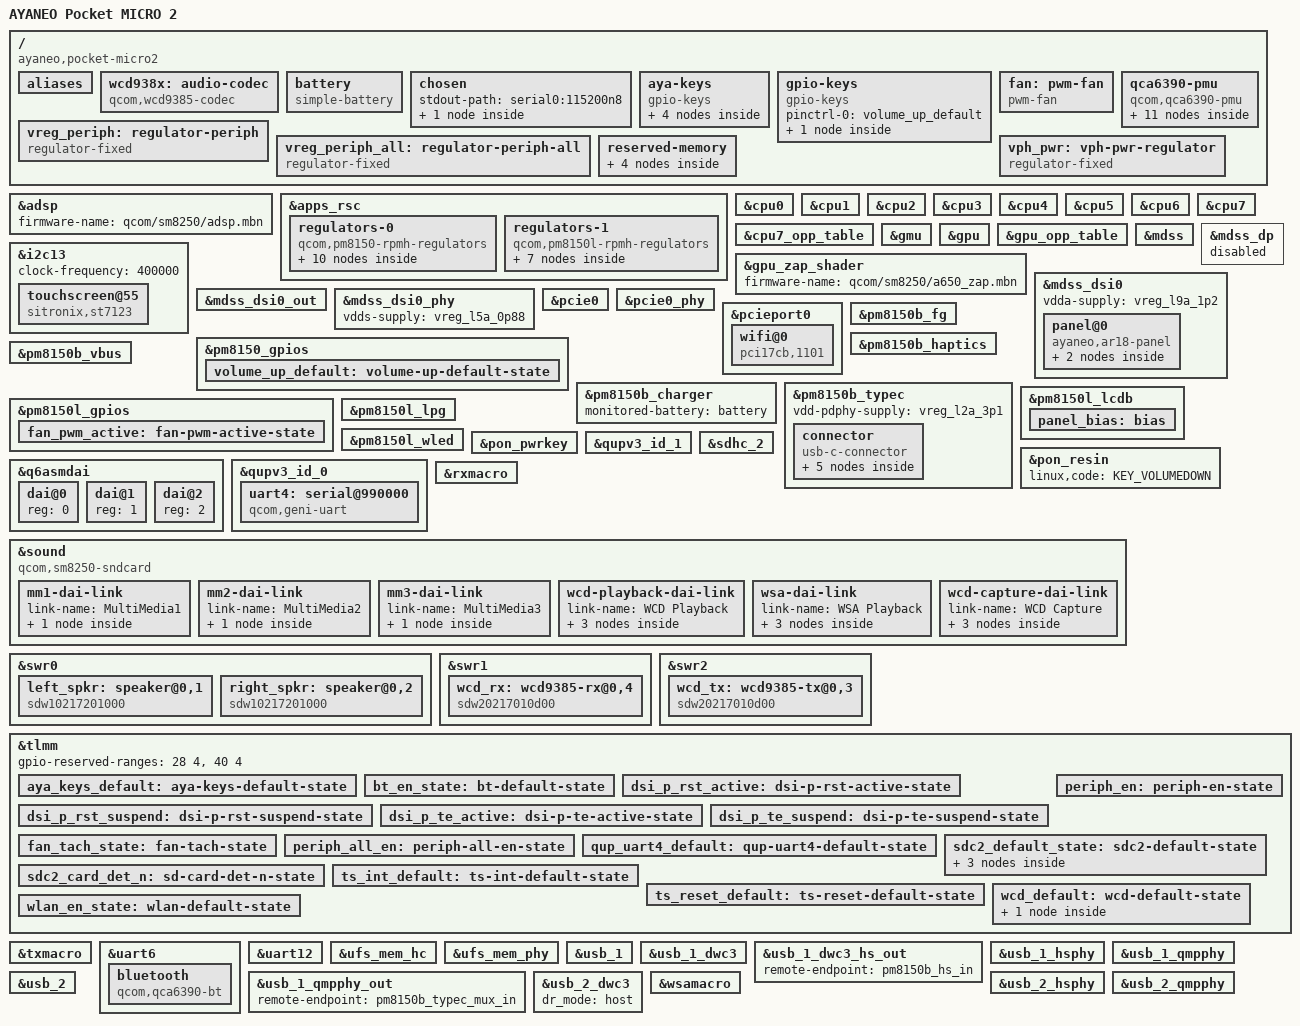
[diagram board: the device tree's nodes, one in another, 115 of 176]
// SPDX-License-Identifier: BSD-3-Clause

/dts-v1/;

#include <dt-bindings/gpio/gpio.h>
#include <dt-bindings/input/input.h>
#include <dt-bindings/interconnect/qcom,icc.h>
#include <dt-bindings/regulator/qcom,rpmh-regulator.h>
#include <dt-bindings/sound/qcom,q6afe.h>
#include <dt-bindings/sound/qcom,q6asm.h>
#include <dt-bindings/usb/pd.h>
#include "sm8250.dtsi"
#include "pm8150.dtsi"
#include "pm8150b.dtsi"
#include "pm8150l.dtsi"

/ {
	model = "AYANEO Pocket MICRO 2";
	compatible = "ayaneo,pocket-micro2", "qcom,sm8250";
	qcom,msm-id = <0x164 0x20001>;
	qcom,board-id = <0x0b 0x00>;

	aliases {
		serial0 = &uart12;
		serial1 = &uart6;
		serial2 = &uart4;
	};

	wcd938x: audio-codec {
		compatible = "qcom,wcd9385-codec";

		pinctrl-names = "default";
		pinctrl-0 = <&wcd_default>;

		reset-gpios = <&tlmm 32 GPIO_ACTIVE_LOW>;

		vdd-buck-supply = <&vreg_s4a_1p8>;
		vdd-rxtx-supply = <&vreg_s4a_1p8>;
		vdd-io-supply = <&vreg_s4a_1p8>;
		vdd-mic-bias-supply = <&vreg_bob>;

		qcom,micbias1-microvolt = <1800000>;
		qcom,micbias2-microvolt = <1800000>;
		qcom,micbias3-microvolt = <1800000>;
		qcom,micbias4-microvolt = <1800000>;
		qcom,mbhc-buttons-vthreshold-microvolt = <75000 150000 237000 500000 500000 500000 500000 500000>;
		qcom,mbhc-headset-vthreshold-microvolt = <1700000>;
		qcom,mbhc-headphone-vthreshold-microvolt = <50000>;
		qcom,hphl-jack-type-normally-closed;
		qcom,ground-jack-type-normally-closed;
		qcom,rx-device = <&wcd_rx>;
		qcom,tx-device = <&wcd_tx>;

		#sound-dai-cells = <1>;
	};

	battery: battery {
		compatible = "simple-battery";

		charge-full-design-microamp-hours = <3950000>;
		voltage-min-design-microvolt = <3600000>;
		voltage-max-design-microvolt = <4450000>;
		constant-charge-current-max-microamp = <3000000>;
	};

	chosen {
		#address-cells = <2>;
		#size-cells = <2>;
		ranges;

		stdout-path = "serial0:115200n8";

		framebuffer: framebuffer@9c000000 {
			compatible = "simple-framebuffer";
			reg = <0x0 0x9c000000 0x0 0x258000>;
			width = <640>;
			height = <960>;
			stride = <(640 * 4)>;
			format = "a8r8g8b8";
		};
	};

	aya-keys {
		compatible = "gpio-keys";
		label = "aya-keys";
		pinctrl-0 = <&aya_keys_default>;
		pinctrl-names = "default";

		key-home {
			label = "Home";
			linux,code = <KEY_PROG1>;
			gpios = <&tlmm 110 GPIO_ACTIVE_LOW>;
			debounce-interval = <15>;
		};

		key-lc {
			label = "LC";
			linux,code = <KEY_PROG3>;
			gpios = <&tlmm 113 GPIO_ACTIVE_LOW>;
			debounce-interval = <15>;
		};

		key-rc {
			label = "RC";
			linux,code = <KEY_PROG4>;
			gpios = <&tlmm 111 GPIO_ACTIVE_LOW>;
			debounce-interval = <15>;
		};

		key-space {
			label = "Space";
			linux,code = <KEY_PROG2>;
			gpios = <&tlmm 109 GPIO_ACTIVE_LOW>;
			debounce-interval = <15>;
		};
	};

	gpio-keys {
		compatible = "gpio-keys";
		pinctrl-0 = <&volume_up_default>;
		pinctrl-names = "default";

		key-vol-up {
			label = "Volume Up";
			linux,code = <KEY_VOLUMEUP>;
			gpios = <&pm8150_gpios 6 GPIO_ACTIVE_LOW>;
			wakeup-source;
		};
	};

	fan: pwm-fan {
		compatible = "pwm-fan";
		cooling-levels = <0 100 130 160 190 210 230 245 255>;
		#cooling-cells = <2>;
		pwms = <&pm8150l_lpg 4 40000>;
		interrupt-parent = <&tlmm>;
		interrupts = <51 IRQ_TYPE_EDGE_FALLING>;
		pulses-per-revolution = <2>;
		pinctrl-names = "default";
		pinctrl-0 = <&fan_pwm_active>, <&fan_tach_state>;
	};

	qca6390-pmu {
		compatible = "qcom,qca6390-pmu";

		pinctrl-names = "default";
		pinctrl-0 = <&bt_en_state>, <&wlan_en_state>;

		vddaon-supply = <&vreg_s6a_0p95>;
		vddrfa1p3-supply = <&vreg_s8c_1p3>;
		vddrfa1p9-supply = <&vreg_s5a_1p9>;
		vddpcie1p3-supply = <&vreg_s8c_1p3>;
		vddpcie1p9-supply = <&vreg_s5a_1p9>;
		vddio-supply = <&vreg_s4a_1p8>;

		wlan-enable-gpios = <&tlmm 20 GPIO_ACTIVE_HIGH>;
		bt-enable-gpios = <&tlmm 21 GPIO_ACTIVE_HIGH>;

		regulators {
			vreg_pmu_rfa_cmn: ldo0 {
				regulator-name = "vreg_pmu_rfa_cmn";
			};

			vreg_pmu_aon_0p59: ldo1 {
				regulator-name = "vreg_pmu_aon_0p59";
			};

			vreg_pmu_wlcx_0p8: ldo2 {
				regulator-name = "vreg_pmu_wlcx_0p8";
			};

			vreg_pmu_wlmx_0p85: ldo3 {
				regulator-name = "vreg_pmu_wlmx_0p85";
			};

			vreg_pmu_btcmx_0p85: ldo4 {
				regulator-name = "vreg_pmu_btcmx_0p85";
			};

			vreg_pmu_rfa_0p8: ldo5 {
				regulator-name = "vreg_pmu_rfa_0p8";
			};

			vreg_pmu_rfa_1p2: ldo6 {
				regulator-name = "vreg_pmu_rfa_1p2";
			};

			vreg_pmu_rfa_1p7: ldo7 {
				regulator-name = "vreg_pmu_rfa_1p7";
			};

			vreg_pmu_pcie_0p9: ldo8 {
				regulator-name = "vreg_pmu_pcie_0p9";
			};

			vreg_pmu_pcie_1p8: ldo9 {
				regulator-name = "vreg_pmu_pcie_1p8";
			};
		};
	};

	vreg_periph: regulator-periph {
		compatible = "regulator-fixed";
		regulator-name = "periph";
		gpio = <&tlmm 119 GPIO_ACTIVE_HIGH>;
		enable-active-high;
		regulator-always-on;
		regulator-boot-on;
		pinctrl-0 = <&periph_en>;
		pinctrl-names = "default";
	};

	vreg_periph_all: regulator-periph-all {
		compatible = "regulator-fixed";
		regulator-name = "periph_all";
		gpio = <&tlmm 12 GPIO_ACTIVE_HIGH>;
		enable-active-high;
		regulator-always-on;
		regulator-boot-on;
		pinctrl-0 = <&periph_all_en>;
		pinctrl-names = "default";
	};

	reserved-memory {
		cont_splash_mem: splash_region@9c000000 {
			reg = <0x0 0x9c000000 0x0 0x2300000>;
			no-map;
		};

		reserved_ea000000_mem: reserved@ea000000 {
			reg = <0x0 0xea000000 0x0 0x15c00000>;
			no-map;
		};

		reserved_ffc00000_mem: reserved@ffc00000 {
			reg = <0x0 0xffc00000 0x0 0x20000>;
			no-map;
		};

		linux,cma {
			compatible = "shared-dma-pool";
			reusable;
			size = <0x0 0x10000000>;
			linux,cma-default;
		};
	};

	vph_pwr: vph-pwr-regulator {
		compatible = "regulator-fixed";
		regulator-name = "vph_pwr";
		regulator-min-microvolt = <3700000>;
		regulator-max-microvolt = <3700000>;
		regulator-always-on;
	};
};

&adsp {
	status = "okay";
	firmware-name = "qcom/sm8250/adsp.mbn";
};

&apps_rsc {
	regulators-0 {
		compatible = "qcom,pm8150-rpmh-regulators";
		qcom,pmic-id = "a";

		vdd-s1-supply = <&vph_pwr>;
		vdd-s2-supply = <&vph_pwr>;
		vdd-s3-supply = <&vph_pwr>;
		vdd-s4-supply = <&vph_pwr>;
		vdd-s5-supply = <&vph_pwr>;
		vdd-s6-supply = <&vph_pwr>;
		vdd-s7-supply = <&vph_pwr>;
		vdd-s8-supply = <&vph_pwr>;
		vdd-s9-supply = <&vph_pwr>;
		vdd-s10-supply = <&vph_pwr>;
		vdd-l2-l10-supply = <&vreg_bob>;
		vdd-l3-l4-l5-l18-supply = <&vreg_s6a_0p95>;
		vdd-l6-l9-supply = <&vreg_s8c_1p3>;
		vdd-l7-l12-l14-l15-supply = <&vreg_s5a_1p9>;
		vdd-l13-l16-l17-supply = <&vreg_bob>;

		vreg_l2a_3p1: ldo2 {
			regulator-name = "vreg_l2a_3p1";
			regulator-min-microvolt = <3072000>;
			regulator-max-microvolt = <3072000>;
			regulator-initial-mode = <RPMH_REGULATOR_MODE_HPM>;
		};

		vreg_l5a_0p88: ldo5 {
			regulator-name = "vreg_l5a_0p88";
			regulator-min-microvolt = <880000>;
			regulator-max-microvolt = <880000>;
			regulator-initial-mode = <RPMH_REGULATOR_MODE_HPM>;
		};

		vreg_l6a_1p2: ldo6 {
			regulator-name = "vreg_l6a_1p2";
			regulator-min-microvolt = <1200000>;
			regulator-max-microvolt = <1200000>;
			regulator-initial-mode = <RPMH_REGULATOR_MODE_HPM>;
		};

		vreg_l9a_1p2: ldo9 {
			regulator-name = "vreg_l9a_1p2";
			regulator-min-microvolt = <1200000>;
			regulator-max-microvolt = <1200000>;
			regulator-initial-mode = <RPMH_REGULATOR_MODE_HPM>;
			regulator-always-on;
			regulator-boot-on;
		};

		vreg_l12a_1p8: ldo12 {
			regulator-name = "vreg_l12a_1p8";
			regulator-min-microvolt = <1800000>;
			regulator-max-microvolt = <1800000>;
			regulator-initial-mode = <RPMH_REGULATOR_MODE_HPM>;
		};

		vreg_l17a_3p0: ldo17 {
			regulator-name = "vreg_l17a_3p0";
			regulator-min-microvolt = <2856000>;
			regulator-max-microvolt = <3008000>;
			regulator-initial-mode = <RPMH_REGULATOR_MODE_HPM>;
		};

		vreg_l18a_0p92: ldo18 {
			regulator-name = "vreg_l18a_0p92";
			regulator-min-microvolt = <800000>;
			regulator-max-microvolt = <912000>;
			regulator-initial-mode = <RPMH_REGULATOR_MODE_HPM>;
			regulator-always-on;
			regulator-boot-on;
		};

		vreg_s4a_1p8: smps4 {
			regulator-name = "vreg_s4a_1p8";
			regulator-min-microvolt = <1800000>;
			regulator-max-microvolt = <1800000>;
			regulator-initial-mode = <RPMH_REGULATOR_MODE_HPM>;
			regulator-always-on;
			regulator-boot-on;
		};

		vreg_s5a_1p9: smps5 {
			regulator-name = "vreg_s5a_1p9";
			regulator-min-microvolt = <1904000>;
			regulator-max-microvolt = <2000000>;
			regulator-initial-mode = <RPMH_REGULATOR_MODE_HPM>;
		};

		vreg_s6a_0p95: smps6 {
			regulator-name = "vreg_s6a_0p95";
			regulator-min-microvolt = <920000>;
			regulator-max-microvolt = <1128000>;
			regulator-initial-mode = <RPMH_REGULATOR_MODE_HPM>;
		};
	};

	regulators-1 {
		compatible = "qcom,pm8150l-rpmh-regulators";
		qcom,pmic-id = "c";

		vdd-s1-supply = <&vph_pwr>;
		vdd-s2-supply = <&vph_pwr>;
		vdd-s3-supply = <&vph_pwr>;
		vdd-s4-supply = <&vph_pwr>;
		vdd-s5-supply = <&vph_pwr>;
		vdd-s6-supply = <&vph_pwr>;
		vdd-s7-supply = <&vph_pwr>;
		vdd-s8-supply = <&vph_pwr>;
		vdd-l1-l8-supply = <&vreg_s4a_1p8>;
		vdd-l2-l3-supply = <&vreg_s8c_1p3>;
		vdd-l4-l5-l6-supply = <&vreg_bob>;
		vdd-l7-l11-supply = <&vreg_bob>;
		vdd-l9-l10-supply = <&vreg_bob>;
		vdd-bob-supply = <&vph_pwr>;

		vreg_bob: bob {
			regulator-name = "vreg_bob";
			regulator-min-microvolt = <3008000>;
			regulator-max-microvolt = <4000000>;
			regulator-initial-mode = <RPMH_REGULATOR_MODE_AUTO>;
		};

		vreg_l1c_ts_1p8: ldo1 {
			regulator-name = "vreg_l1c_ts_1p8";
			regulator-min-microvolt = <1800000>;
			regulator-max-microvolt = <1800000>;
			regulator-initial-mode = <RPMH_REGULATOR_MODE_HPM>;
			regulator-always-on;
		};

		vreg_l6c_2p96: ldo6 {
			regulator-name = "vreg_l6c_2p96";
			regulator-min-microvolt = <1800000>;
			regulator-max-microvolt = <2960000>;
			regulator-initial-mode = <RPMH_REGULATOR_MODE_HPM>;
		};

		vreg_l9c_2p96: ldo9 {
			regulator-name = "vreg_l9c_2p96";
			regulator-min-microvolt = <2704000>;
			regulator-max-microvolt = <2960000>;
			regulator-initial-mode = <RPMH_REGULATOR_MODE_HPM>;
		};

		vreg_l10c_3p0: ldo10 {
			regulator-name = "vreg_l10c_3p0";
			regulator-min-microvolt = <3000000>;
			regulator-max-microvolt = <3312000>;
			regulator-initial-mode = <RPMH_REGULATOR_MODE_HPM>;
			regulator-always-on;
		};

		vreg_l11c_3p3: ldo11 {
			regulator-name = "vreg_l11c_3p3";
			regulator-min-microvolt = <3296000>;
			regulator-max-microvolt = <3296000>;
			regulator-initial-mode = <RPMH_REGULATOR_MODE_HPM>;
			regulator-always-on;
		};

		vreg_s8c_1p3: smps8 {
			regulator-name = "vreg_s8c_1p3";
			regulator-min-microvolt = <1352000>;
			regulator-max-microvolt = <1352000>;
			regulator-initial-mode = <RPMH_REGULATOR_MODE_HPM>;
		};
	};
};

&cpu0 {
	interconnects = <&gem_noc MASTER_AMPSS_M0 QCOM_ICC_TAG_ACTIVE_ONLY &mc_virt SLAVE_EBI_CH0 QCOM_ICC_TAG_ACTIVE_ONLY>,
			<&epss_l3 MASTER_OSM_L3_APPS &epss_l3 SLAVE_OSM_L3>;
};

&cpu1 {
	interconnects = <&gem_noc MASTER_AMPSS_M0 QCOM_ICC_TAG_ACTIVE_ONLY &mc_virt SLAVE_EBI_CH0 QCOM_ICC_TAG_ACTIVE_ONLY>,
			<&epss_l3 MASTER_OSM_L3_APPS &epss_l3 SLAVE_OSM_L3>;
};

&cpu2 {
	interconnects = <&gem_noc MASTER_AMPSS_M0 QCOM_ICC_TAG_ACTIVE_ONLY &mc_virt SLAVE_EBI_CH0 QCOM_ICC_TAG_ACTIVE_ONLY>,
			<&epss_l3 MASTER_OSM_L3_APPS &epss_l3 SLAVE_OSM_L3>;
};

&cpu3 {
	interconnects = <&gem_noc MASTER_AMPSS_M0 QCOM_ICC_TAG_ACTIVE_ONLY &mc_virt SLAVE_EBI_CH0 QCOM_ICC_TAG_ACTIVE_ONLY>,
			<&epss_l3 MASTER_OSM_L3_APPS &epss_l3 SLAVE_OSM_L3>;
};

&cpu4 {
	interconnects = <&gem_noc MASTER_AMPSS_M0 QCOM_ICC_TAG_ACTIVE_ONLY &mc_virt SLAVE_EBI_CH0 QCOM_ICC_TAG_ACTIVE_ONLY>,
			<&epss_l3 MASTER_OSM_L3_APPS &epss_l3 SLAVE_OSM_L3>;
};

&cpu5 {
	interconnects = <&gem_noc MASTER_AMPSS_M0 QCOM_ICC_TAG_ACTIVE_ONLY &mc_virt SLAVE_EBI_CH0 QCOM_ICC_TAG_ACTIVE_ONLY>,
			<&epss_l3 MASTER_OSM_L3_APPS &epss_l3 SLAVE_OSM_L3>;
};

&cpu6 {
	interconnects = <&gem_noc MASTER_AMPSS_M0 QCOM_ICC_TAG_ACTIVE_ONLY &mc_virt SLAVE_EBI_CH0 QCOM_ICC_TAG_ACTIVE_ONLY>,
			<&epss_l3 MASTER_OSM_L3_APPS &epss_l3 SLAVE_OSM_L3>;
};

&cpu7 {
	interconnects = <&gem_noc MASTER_AMPSS_M0 QCOM_ICC_TAG_ACTIVE_ONLY &mc_virt SLAVE_EBI_CH0 QCOM_ICC_TAG_ACTIVE_ONLY>,
			<&epss_l3 MASTER_OSM_L3_APPS &epss_l3 SLAVE_OSM_L3>;
};

&cpu7_opp_table {
	/delete-node/ opp-2745600000;
	/delete-node/ opp-2841600000;
};

&gmu {
	status = "okay";
};

&gpu {
	status = "okay";
};

&gpu_opp_table {
	/delete-node/ opp-925000000;
	/delete-node/ opp-905000000;
	/delete-node/ opp-855000000;
	/delete-node/ opp-800000000;
	/delete-node/ opp-750000000;
	/delete-node/ opp-725000000;
	/delete-node/ opp-700000000;
	/delete-node/ opp-670000000;
	/delete-node/ opp-650000000;
};

&gpu_zap_shader {
	firmware-name = "qcom/sm8250/a650_zap.mbn";
};

&i2c13 {
	status = "okay";
	clock-frequency = <400000>;

	touchscreen@55 {
		compatible = "sitronix,st7123";
		reg = <0x55>;
		interrupt-parent = <&tlmm>;
		interrupts = <39 IRQ_TYPE_EDGE_FALLING>;
		reset-gpios = <&tlmm 38 GPIO_ACTIVE_LOW>;
		touchscreen-size-x = <640>;
		touchscreen-size-y = <960>;
		pinctrl-0 = <&ts_int_default &ts_reset_default>;
		pinctrl-names = "default";
	};
};

&mdss {
	status = "okay";
};

&mdss_dp {
	status = "disabled";
};

&mdss_dsi0 {
	status = "okay";
	vdda-supply = <&vreg_l9a_1p2>;

	panel@0 {
		reg = <0>;
		compatible = "ayaneo,ar18-panel";
		rotation = <90>;

		pinctrl-0 = <&dsi_p_rst_active>, <&dsi_p_te_active>;
		pinctrl-1 = <&dsi_p_rst_suspend>, <&dsi_p_te_suspend>;
		pinctrl-names = "default", "sleep";

		backlight = <&pm8150l_wled>;

		vddio-supply = <&vreg_l12a_1p8>;
		lab-supply = <&panel_bias>;

		reset-gpios = <&tlmm 75 GPIO_ACTIVE_LOW>;

		port {
			panel0_in: endpoint {
				remote-endpoint = <&mdss_dsi0_out>;
			};
		};
	};
};

&mdss_dsi0_out {
	remote-endpoint = <&panel0_in>;
	data-lanes = <0 1 2 3>;
};

&mdss_dsi0_phy {
	status = "okay";
	vdds-supply = <&vreg_l5a_0p88>;
};

&pcie0 {
	status = "okay";
};

&pcie0_phy {
	status = "okay";
	vdda-phy-supply = <&vreg_l5a_0p88>;
	vdda-pll-supply = <&vreg_l9a_1p2>;
};

&pcieport0 {
	wifi@0 {
		compatible = "pci17cb,1101";
		reg = <0x10000 0x0 0x0 0x0 0x0>;

		vddrfacmn-supply = <&vreg_pmu_rfa_cmn>;
		vddaon-supply = <&vreg_pmu_aon_0p59>;
		vddwlcx-supply = <&vreg_pmu_wlcx_0p8>;
		vddwlmx-supply = <&vreg_pmu_wlmx_0p85>;
		vddrfa0p8-supply = <&vreg_pmu_rfa_0p8>;
		vddrfa1p2-supply = <&vreg_pmu_rfa_1p2>;
		vddrfa1p7-supply = <&vreg_pmu_rfa_1p7>;
		vddpcie0p9-supply = <&vreg_pmu_pcie_0p9>;
		vddpcie1p8-supply = <&vreg_pmu_pcie_1p8>;
	};
};

&pm8150_gpios {
	volume_up_default: volume-up-default-state {
		pins = "gpio6";
		function = "normal";
		bias-pull-up;
	};
};

&pm8150b_charger {
	monitored-battery = <&battery>;
	status = "okay";
};

&pm8150b_fg {
	status = "okay";
	monitored-battery = <&battery>;
	power-supplies = <&pm8150b_charger>;
};

&pm8150b_haptics {
	status = "okay";
	qcom,boost-gpios = <&pm8150b_gpios 5 GPIO_ACTIVE_HIGH>;
	qcom,wave-play-rate-us = <5882>;
	qcom,actuator-type = <HAP_TYPE_LRA>;
};

&pm8150b_typec {
	status = "okay";

	vdd-pdphy-supply = <&vreg_l2a_3p1>;

	connector {
		compatible = "usb-c-connector";

		power-role = "dual";
		data-role = "dual";
		try-power-role = "sink";
		self-powered;

		vbus-supply = <&pm8150b_vbus>;

		source-pdos = <PDO_FIXED(5000, 3000,
					 PDO_FIXED_DUAL_ROLE |
					 PDO_FIXED_USB_COMM |
					 PDO_FIXED_DATA_SWAP)>;

		sink-pdos = <PDO_FIXED(5000, 3000,
					 PDO_FIXED_DUAL_ROLE |
					 PDO_FIXED_USB_COMM |
					 PDO_FIXED_DATA_SWAP)>;

		op-sink-microwatt = <15000000>;

		ports {
			#address-cells = <1>;
			#size-cells = <0>;

			port@0 {
				reg = <0>;
				pm8150b_hs_in: endpoint {
					remote-endpoint = <&usb_1_dwc3_hs_out>;
				};
			};

			port@1 {
				reg = <1>;
				pm8150b_typec_mux_in: endpoint {
					remote-endpoint = <&usb_1_qmpphy_out>;
				};
			};
		};
	};
};

&pm8150b_vbus {
	regulator-min-microamp = <500000>;
	regulator-max-microamp = <3000000>;
	status = "okay";
};

&pm8150l_gpios {
	fan_pwm_active: fan-pwm-active-state {
		pins = "gpio10";
		function = "func1";
		power-source = <1>;
		drive-push-pull;
		qcom,drive-strength = <3>;
		output-enable;
		bias-disable;
	};
};

&pm8150l_lcdb {
	status = "okay";

	panel_bias: bias {
		regulator-name = "panel_bias";
		regulator-min-microvolt = <5500000>;
		regulator-max-microvolt = <5500000>;
	};
};

&pm8150l_lpg {
	status = "okay";
};

&pm8150l_wled {
	status = "okay";

	default-brightness = <1000>;
	max-brightness = <4095>;
	qcom,enabled-strings = <0 1 2>;
};

&pon_pwrkey {
	status = "okay";
};

&pon_resin {
	linux,code = <KEY_VOLUMEDOWN>;
	status = "okay";
};

&q6asmdai {
	dai@0 {
		reg = <0>;
	};

	dai@1 {
		reg = <1>;
	};

	dai@2 {
		reg = <2>;
	};
};

&qupv3_id_0 {
	status = "okay";

	uart4: serial@990000 {
		compatible = "qcom,geni-uart";
		reg = <0 0x00990000 0 0x4000>;
		clock-names = "se";
		clocks = <&gcc GCC_QUPV3_WRAP0_S4_CLK>;
		pinctrl-names = "default";
		pinctrl-0 = <&qup_uart4_default>;
		interrupts = <GIC_SPI 605 IRQ_TYPE_LEVEL_HIGH>;
		power-domains = <&rpmhpd RPMHPD_CX>;
		operating-points-v2 = <&qup_opp_table>;
		interconnects = <&qup_virt MASTER_QUP_CORE_0 0 &qup_virt SLAVE_QUP_CORE_0 0>,
				<&gem_noc MASTER_AMPSS_M0 0 &config_noc SLAVE_QUP_0 0>;
		interconnect-names = "qup-core",
				     "qup-config";
		status = "okay";
	};
};

&qupv3_id_1 {
	status = "okay";
};

&rxmacro {
	status = "okay";
};

&sdhc_2 {
	status = "okay";
	pinctrl-names = "default";
	pinctrl-0 = <&sdc2_default_state &sdc2_card_det_n>;

	vmmc-supply = <&vreg_l9c_2p96>;
	vqmmc-supply = <&vreg_l6c_2p96>;
	cd-gpios = <&tlmm 77 GPIO_ACTIVE_LOW>;
	bus-width = <4>;
	no-sdio;
	no-mmc;
};

&sound {
	compatible = "qcom,sm8250-sndcard";
	model = "PocketMICRO2";
	audio-routing =
		"SpkrLeft IN", "WSA_SPK1 OUT",
		"SpkrRight IN", "WSA_SPK2 OUT",
		"IN1_HPHL", "HPHL_OUT",
		"IN2_HPHR", "HPHR_OUT",
		"AMIC1", "MIC BIAS1",
		"AMIC2", "MIC BIAS2",
		"AMIC3", "MIC BIAS3",
		"AMIC4", "MIC BIAS3",
		"AMIC5", "MIC BIAS4",
		"TX SWR_ADC0", "ADC1_OUTPUT",
		"TX SWR_ADC1", "ADC2_OUTPUT",
		"TX SWR_ADC2", "ADC3_OUTPUT",
		"TX SWR_ADC3", "ADC4_OUTPUT",
		"TX SWR_DMIC0", "DMIC1_OUTPUT",
		"TX SWR_DMIC1", "DMIC2_OUTPUT",
		"TX SWR_DMIC2", "DMIC3_OUTPUT",
		"TX SWR_DMIC3", "DMIC4_OUTPUT",
		"TX SWR_DMIC4", "DMIC5_OUTPUT",
		"TX SWR_DMIC5", "DMIC6_OUTPUT",
		"TX SWR_DMIC6", "DMIC7_OUTPUT",
		"TX SWR_DMIC7", "DMIC8_OUTPUT";

	mm1-dai-link {
		link-name = "MultiMedia1";
		cpu {
			sound-dai = <&q6asmdai MSM_FRONTEND_DAI_MULTIMEDIA1>;
		};
	};

	mm2-dai-link {
		link-name = "MultiMedia2";
		cpu {
			sound-dai = <&q6asmdai MSM_FRONTEND_DAI_MULTIMEDIA2>;
		};
	};

	mm3-dai-link {
		link-name = "MultiMedia3";
		cpu {
			sound-dai = <&q6asmdai MSM_FRONTEND_DAI_MULTIMEDIA3>;
		};
	};

	wcd-playback-dai-link {
		link-name = "WCD Playback";
		cpu {
			sound-dai = <&q6afedai RX_CODEC_DMA_RX_0>;
		};
		codec {
			sound-dai = <&wcd938x 0>, <&swr1 0>, <&rxmacro 0>;
		};
		platform {
			sound-dai = <&q6routing>;
		};
	};

	wsa-dai-link {
		link-name = "WSA Playback";
		cpu {
			sound-dai = <&q6afedai WSA_CODEC_DMA_RX_0>;
		};
		codec {
			sound-dai = <&left_spkr>, <&right_spkr>, <&swr0 0>, <&wsamacro 0>;
		};
		platform {
			sound-dai = <&q6routing>;
		};
	};

	wcd-capture-dai-link {
		link-name = "WCD Capture";
		cpu {
			sound-dai = <&q6afedai TX_CODEC_DMA_TX_3>;
		};
		codec {
			sound-dai = <&wcd938x 1>, <&swr2 0>, <&txmacro 0>;
		};
		platform {
			sound-dai = <&q6routing>;
		};
	};
};

&swr0 {
	status = "okay";

	left_spkr: speaker@0,1 {
		compatible = "sdw10217201000";
		reg = <0 1>;
		powerdown-gpios = <&tlmm 129 GPIO_ACTIVE_LOW>;
		#thermal-sensor-cells = <0>;
		sound-name-prefix = "SpkrLeft";
		#sound-dai-cells = <0>;
	};

	right_spkr: speaker@0,2 {
		compatible = "sdw10217201000";
		reg = <0 2>;
		powerdown-gpios = <&tlmm 127 GPIO_ACTIVE_LOW>;
		#thermal-sensor-cells = <0>;
		sound-name-prefix = "SpkrRight";
		#sound-dai-cells = <0>;
	};
};

&swr1 {
	status = "okay";

	wcd_rx: wcd9385-rx@0,4 {
		compatible = "sdw20217010d00";
		reg = <0 4>;
		qcom,rx-port-mapping = <1 2 3 4 5>;
	};
};

&swr2 {
	status = "okay";

	wcd_tx: wcd9385-tx@0,3 {
		compatible = "sdw20217010d00";
		reg = <0 3>;
		qcom,tx-port-mapping = <2 3 4 5>;
	};
};

&tlmm {
	gpio-reserved-ranges = <28 4>, <40 4>;

	aya_keys_default: aya-keys-default-state {
		pins = "gpio109", "gpio110", "gpio111", "gpio113";
		function = "gpio";
		drive-strength = <2>;
		bias-pull-up;
	};

	bt_en_state: bt-default-state {
		pins = "gpio21";
		function = "gpio";
		drive-strength = <16>;
		output-low;
		bias-pull-up;
	};

	dsi_p_rst_active: dsi-p-rst-active-state {
		pins = "gpio75";
		function = "gpio";
		drive-strength = <8>;
		bias-disable;
	};

	dsi_p_rst_suspend: dsi-p-rst-suspend-state {
		pins = "gpio75";
		function = "gpio";
		drive-strength = <2>;
		bias-pull-down;
	};

	dsi_p_te_active: dsi-p-te-active-state {
		pins = "gpio66";
		function = "mdp_vsync";
		drive-strength = <2>;
		bias-pull-down;
	};

	dsi_p_te_suspend: dsi-p-te-suspend-state {
		pins = "gpio66";
		function = "mdp_vsync";
		drive-strength = <2>;
		bias-pull-down;
	};

	fan_tach_state: fan-tach-state {
		pins = "gpio51";
		function = "gpio";
		drive-strength = <2>;
		bias-disable;
	};

	periph_all_en: periph-all-en-state {
		pins = "gpio12";
		function = "gpio";
		drive-strength = <2>;
		bias-disable;
		output-high;
	};

	periph_en: periph-en-state {
		pins = "gpio119";
		function = "gpio";
		drive-strength = <2>;
		bias-disable;
		output-high;
	};

	qup_uart4_default: qup-uart4-default-state {
		pins = "gpio10", "gpio11";
		function = "qup4";
		drive-strength = <2>;
		bias-pull-up;
	};

	sdc2_default_state: sdc2-default-state {
		clk-pins {
			pins = "sdc2_clk";
			bias-disable;
			drive-strength = <16>;
		};

		cmd-pins {
			pins = "sdc2_cmd";
			bias-pull-up;
			drive-strength = <10>;
		};

		data-pins {
			pins = "sdc2_data";
			bias-pull-up;
			drive-strength = <10>;
		};
	};

	sdc2_card_det_n: sd-card-det-n-state {
		pins = "gpio77";
		function = "gpio";
		bias-pull-up;
	};

	ts_int_default: ts-int-default-state {
		pins = "gpio39";
		function = "gpio";
		drive-strength = <8>;
		bias-pull-up;
	};

	ts_reset_default: ts-reset-default-state {
		pins = "gpio38";
		function = "gpio";
		drive-strength = <8>;
		bias-pull-up;
	};

	wcd_default: wcd-default-state {
		reset-pins {
			pins = "gpio32";
			function = "gpio";
			bias-disable;
		};
	};

	wlan_en_state: wlan-default-state {
		pins = "gpio20";
		function = "gpio";
		drive-strength = <16>;
		output-low;
		bias-pull-up;
	};
};

&txmacro {
	status = "okay";
};

&uart6 {
	status = "okay";

	bluetooth {
		compatible = "qcom,qca6390-bt";

		vddrfacmn-supply = <&vreg_pmu_rfa_cmn>;
		vddaon-supply = <&vreg_pmu_aon_0p59>;
		vddbtcmx-supply = <&vreg_pmu_btcmx_0p85>;
		vddrfa0p8-supply = <&vreg_pmu_rfa_0p8>;
		vddrfa1p2-supply = <&vreg_pmu_rfa_1p2>;
		vddrfa1p7-supply = <&vreg_pmu_rfa_1p7>;
	};
};

&uart12 {
	status = "okay";
};

&ufs_mem_hc {
	status = "okay";

	vcc-supply = <&vreg_l17a_3p0>;
	vcc-max-microamp = <800000>;
	vccq-supply = <&vreg_l6a_1p2>;
	vccq2-supply = <&vreg_s4a_1p8>;
};

&ufs_mem_phy {
	status = "okay";

	vdda-phy-supply = <&vreg_l5a_0p88>;
	vdda-pll-supply = <&vreg_l9a_1p2>;
};

&usb_1 {
	status = "okay";
};

&usb_1_dwc3 {
	dr_mode = "otg";
	usb-role-switch;
};

&usb_1_dwc3_hs_out {
	remote-endpoint = <&pm8150b_hs_in>;
};

&usb_1_hsphy {
	status = "okay";

	vdda-pll-supply = <&vreg_l5a_0p88>;
	vdda33-supply = <&vreg_l2a_3p1>;
	vdda18-supply = <&vreg_l12a_1p8>;
};

&usb_1_qmpphy {
	status = "okay";

	vdda-phy-supply = <&vreg_l9a_1p2>;
	vdda-pll-supply = <&vreg_l18a_0p92>;
};

&usb_1_qmpphy_out {
	remote-endpoint = <&pm8150b_typec_mux_in>;
};

&usb_2 {
	status = "okay";
};

&usb_2_dwc3 {
	dr_mode = "host";
};

&usb_2_hsphy {
	status = "okay";

	vdda-pll-supply = <&vreg_l5a_0p88>;
	vdda33-supply = <&vreg_l2a_3p1>;
	vdda18-supply = <&vreg_l12a_1p8>;
};

&usb_2_qmpphy {
	status = "okay";

	vdda-phy-supply = <&vreg_l9a_1p2>;
	vdda-pll-supply = <&vreg_l18a_0p92>;
};

&wsamacro {
	status = "okay";
};
